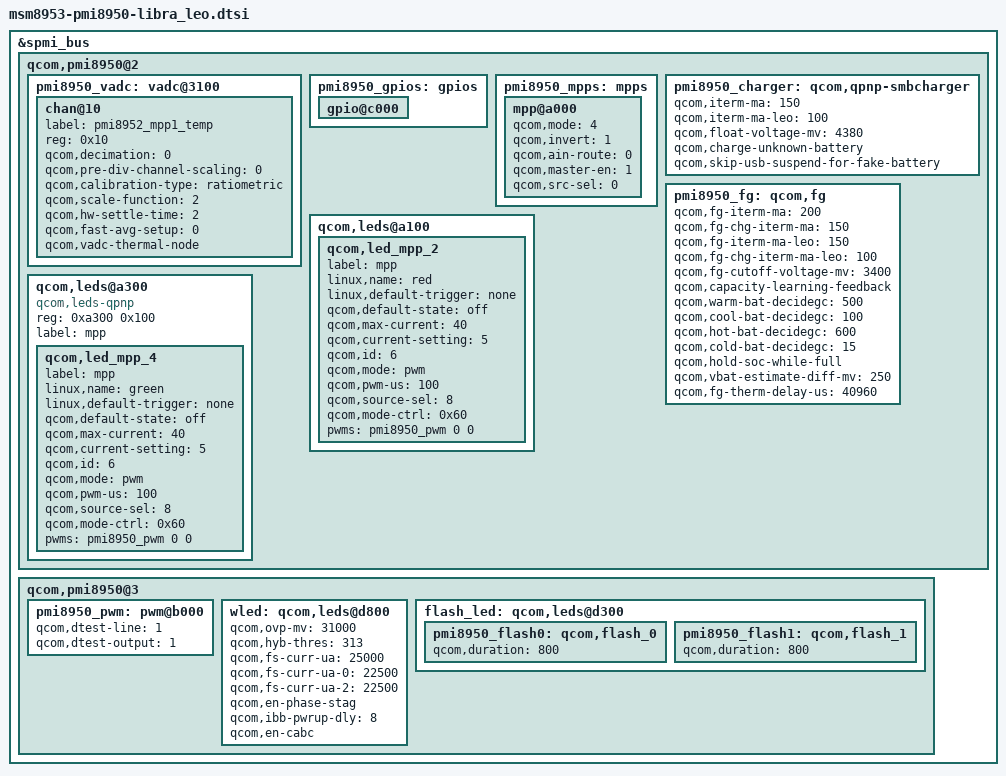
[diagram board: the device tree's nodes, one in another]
&spmi_bus {
	qcom,pmi8950@2 {
		pmi8950_vadc: vadc@3100 {
			chan@10 {
				label = "pmi8952_mpp1_temp";
				reg = <0x10>;
				qcom,decimation = <0>;
				qcom,pre-div-channel-scaling = <0>;
				qcom,calibration-type = "ratiometric";
				qcom,scale-function = <2>;
				qcom,hw-settle-time = <2>;
				qcom,fast-avg-setup = <0>;
				qcom,vadc-thermal-node;
			};
		};

		pmi8950_gpios: gpios {
			gpio@c000 {
				status = "ok";
			};
		};

		pmi8950_mpps: mpps {
			mpp@a000 {
				qcom,mode = <4>;
				qcom,invert = <1>;
				qcom,ain-route = <0>;
				qcom,master-en = <1>;
				qcom,src-sel = <0>;
			};
		};

		pmi8950_charger: qcom,qpnp-smbcharger {
			qcom,iterm-ma = <150>;
			qcom,iterm-ma-leo = <100>;
			qcom,float-voltage-mv = <4380>;
			/delete-property/ qcom,chg-inhibit-fg;
			/delete-property/ qcom,thermal-mitigation;
			/delete-property/ qcom,parallel-usb-min-current-ma;
			/delete-property/ qcom,parallel-usb-9v-min-current-ma;
			/delete-property/ qcom,parallel-allowed-lowering-ma;
			qcom,charge-unknown-battery;
			qcom,skip-usb-suspend-for-fake-battery;
		};

		pmi8950_fg: qcom,fg {
			qcom,fg-iterm-ma = <200>;
			qcom,fg-chg-iterm-ma = <150>;
			qcom,fg-iterm-ma-leo = <150>;
			qcom,fg-chg-iterm-ma-leo = <100>;
			qcom,fg-cutoff-voltage-mv = <3400>;
			qcom,capacity-learning-feedback;
			qcom,warm-bat-decidegc = <500>;
			qcom,cool-bat-decidegc = <100>;
			qcom,hot-bat-decidegc = <600>;
			qcom,cold-bat-decidegc = <15>;
			qcom,hold-soc-while-full;
			qcom,vbat-estimate-diff-mv = <250>;
			qcom,fg-therm-delay-us = <40960>;
		};

		qcom,leds@a100 {
			status = "okay";
			qcom,led_mpp_2 {
				label = "mpp";
				linux,name = "red";
				linux,default-trigger = "none";
				qcom,default-state = "off";
				qcom,max-current = <40>;
				qcom,current-setting = <5>;
				qcom,id = <6>;
				qcom,mode = "pwm";
				qcom,pwm-us = <100>;
				qcom,source-sel = <8>;
				qcom,mode-ctrl = <0x60>;
				pwms = <&pmi8950_pwm 0 0>;
			};
		};

		qcom,leds@a300 {
			compatible = "qcom,leds-qpnp";
			reg = <0xa300 0x100>;
			label = "mpp";
			status = "okay";
			qcom,led_mpp_4 {
				label = "mpp";
				linux,name = "green";
				linux,default-trigger = "none";
				qcom,default-state = "off";
				qcom,max-current = <40>;
				qcom,current-setting = <5>;
				qcom,id = <6>;
				qcom,mode = "pwm";
				qcom,pwm-us = <100>;
				qcom,source-sel = <8>;
				qcom,mode-ctrl = <0x60>;
				pwms = <&pmi8950_pwm 0 0>;
			};
		};
	};

	qcom,pmi8950@3 {
		pmi8950_pwm: pwm@b000 {
			status = "okay";
			qcom,dtest-line = <1>;
			qcom,dtest-output = <1>;
		};

		wled: qcom,leds@d800 {
			qcom,ovp-mv = <31000>;
			qcom,hyb-thres = <313>;
			qcom,fs-curr-ua = <25000>;
			qcom,fs-curr-ua-0 = <22500>;
			qcom,fs-curr-ua-2 = <22500>;
			qcom,en-phase-stag;
			qcom,ibb-pwrup-dly = <8>;
			/delete-property/ qcom,en-ext-pfet-sc-pro;
			qcom,en-cabc;
		};

		flash_led: qcom,leds@d300 {
			pmi8950_flash0: qcom,flash_0 {
				qcom,duration = <800>;
			};

			pmi8950_flash1: qcom,flash_1 {
				qcom,duration = <800>;
			};
		};
	};
};

